BO_ 437 FR_CMR_03_50ms: 32 FR_CMR
 SG_ ID_CIPV : 192|7@1+ (1,0) [0|127] "" Dummy
 SG_ Relative_Velocity : 200|12@1+ (0.05,-100) [-100|104.75] "m/s" Dummy
 SG_ Longitudinal_Distance : 212|12@1+ (0.05,0) [0|204.75] "m" Dummy

BO_ 442 BLINDSPOTS_REAR_CORNERS: 24 XXX
 SG_ CHECKSUM : 0|16@1+ (1,0) [0|65535] "" XXX
 SG_ COUNTER : 16|8@1+ (1,0) [0|255] "" XXX
 SG_ LEFT_BLOCKED : 24|1@0+ (1,0) [0|1] "" XXX
 SG_ LEFT_MB : 30|1@0+ (1,0) [0|3] "" XXX
 SG_ MORE_LEFT_PROB : 32|1@1+ (1,0) [0|3] "" XXX
 SG_ FL_INDICATOR : 46|6@0+ (1,0) [0|1] "" XXX
 SG_ FR_INDICATOR : 54|6@0+ (1,0) [0|63] "" XXX
 SG_ RIGHT_BLOCKED : 64|1@0+ (1,0) [0|1] "" XXX
 SG_ COLLISION_AVOIDANCE_ACTIVE : 68|1@0+ (1,0) [0|1] "" XXX
 SG_ NEW_SIGNAL_2 : 96|1@0+ (1,0) [0|1] "" XXX
 SG_ FL_INDICATOR_ALT : 138|1@0+ (1,0) [0|1] "" XXX
 SG_ FR_INDICATOR_ALT : 141|1@0+ (1,0) [0|1] "" XXX

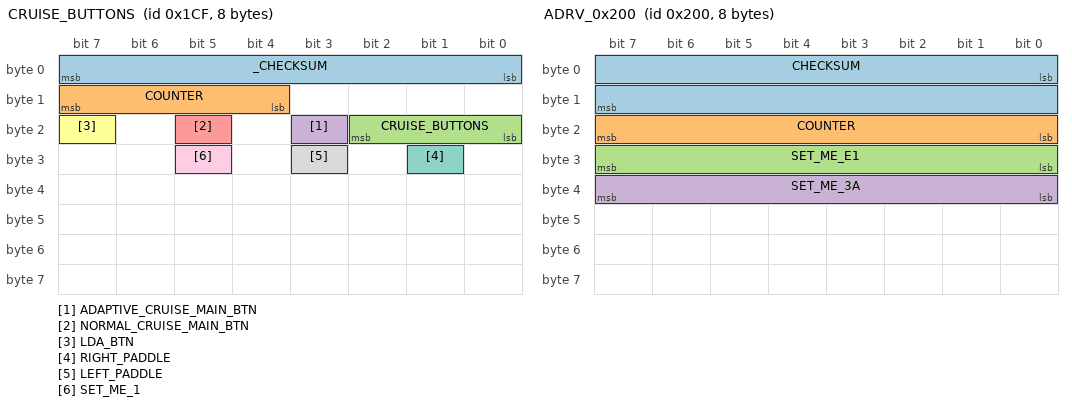
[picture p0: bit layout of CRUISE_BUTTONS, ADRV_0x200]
BO_ 463 CRUISE_BUTTONS: 8 XXX
 SG_ _CHECKSUM : 0|8@1+ (1,0) [0|65535] "" XXX
 SG_ COUNTER : 12|4@1+ (1,0) [0|255] "" XXX
 SG_ CRUISE_BUTTONS : 16|3@1+ (1,0) [0|3] "" XXX
 SG_ ADAPTIVE_CRUISE_MAIN_BTN : 19|1@1+ (1,0) [0|1] "" XXX
 SG_ NORMAL_CRUISE_MAIN_BTN : 21|1@1+ (1,0) [0|1] "" XXX
 SG_ LDA_BTN : 23|1@1+ (1,0) [0|1] "" XXX
 SG_ RIGHT_PADDLE : 25|1@1+ (1,0) [0|1] "" XXX
 SG_ LEFT_PADDLE : 27|1@1+ (1,0) [0|1] "" XXX
 SG_ SET_ME_1 : 29|1@1+ (1,0) [0|1] "" XXX

BO_ 474 ADRV_0x1da: 32 ADRV
 SG_ CHECKSUM : 0|16@1+ (1,0) [0|65535] "" XXX
 SG_ COUNTER : 16|8@1+ (1,0) [0|255] "" XXX
 SG_ SET_ME_22 : 31|8@0+ (1,0) [0|255] "" XXX
 SG_ SET_ME_41 : 47|8@0+ (1,0) [0|255] "" XXX

BO_ 480 LFAHDA_CLUSTER: 16 ADRV
 SG_ CHECKSUM : 0|16@1+ (1,0) [0|65535] "" XXX
 SG_ COUNTER : 16|8@1+ (1,0) [0|255] "" XXX
 SG_ NEW_SIGNAL_4 : 24|1@0+ (1,0) [0|1] "" XXX
 SG_ NEW_SIGNAL_5 : 25|1@0+ (1,0) [0|1] "" XXX
 SG_ NEW_SIGNAL_2 : 30|1@0+ (1,0) [0|1] "" XXX
 SG_ HDA_ICON : 31|1@1+ (1,0) [0|1] "" XXX
 SG_ NEW_SIGNAL_1 : 32|3@1+ (1,0) [0|7] "" XXX
 SG_ LFA_ICON : 47|2@1+ (1,0) [0|3] "" XXX
 SG_ NEW_SIGNAL_3 : 49|1@0+ (1,0) [0|1] "" XXX

BO_ 485 BLINDSPOTS_FRONT_CORNER_1: 16 XXX
 SG_ CHECKSUM : 0|16@1+ (1,0) [0|65535] "" XXX
 SG_ COUNTER : 16|8@1+ (1,0) [0|255] "" XXX
 SG_ REVERSING : 24|1@0+ (1,0) [0|1] "" XXX
 SG_ NEW_SIGNAL_5 : 31|2@0+ (1,0) [0|3] "" XXX
 SG_ NEW_SIGNAL_7 : 32|2@1+ (1,0) [0|3] "" XXX
 SG_ NEW_SIGNAL_8 : 47|8@0+ (1,0) [0|255] "" XXX
 SG_ NEW_SIGNAL_9 : 55|8@0+ (1,0) [0|255] "" XXX
 SG_ NEW_SIGNAL_4 : 80|1@0+ (1,0) [0|1] "" XXX
 SG_ NEW_SIGNAL_3 : 88|1@0+ (1,0) [0|1] "" XXX
 SG_ NEW_SIGNAL_2 : 96|1@0+ (1,0) [0|1] "" XXX
 SG_ NEW_SIGNAL_1 : 108|2@0+ (1,0) [0|3] "" XXX

BO_ 490 ADRV_0x1ea: 32 ADRV
 SG_ CHECKSUM : 0|16@1+ (1,0) [0|65535] "" XXX
 SG_ COUNTER : 16|8@1+ (1,0) [0|255] "" XXX
 SG_ SET_ME_1C : 31|8@0+ (1,0) [0|255] "" XXX
 SG_ NEW_SIGNAL_1 : 32|2@1+ (1,0) [0|3] "" XXX
 SG_ NEW_SIGNAL_2 : 47|2@0+ (1,0) [0|3] "" XXX
 SG_ NEW_SIGNAL_3 : 55|8@0+ (1,0) [0|255] "" XXX
 SG_ NEW_SIGNAL_4 : 64|6@1+ (1,0) [0|31] "" XXX
 SG_ NEW_SIGNAL_5 : 72|2@1+ (1,0) [0|3] "" XXX
 SG_ NEW_SIGNAL_6 : 75|5@1+ (1,0) [0|31] "" XXX
 SG_ NEW_SIGNAL_7 : 80|5@1+ (1,0) [0|31] "" XXX
 SG_ NEW_SIGNAL_8 : 88|7@1+ (1,0) [0|127] "" XXX
 SG_ NEW_SIGNAL_9 : 96|1@0+ (1,0) [0|1] "" XXX
 SG_ SET_ME_FF : 120|8@1+ (1,0) [0|255] "" XXX
 SG_ NEW_SIGNAL_10 : 143|5@0+ (1,0) [0|31] "" XXX
 SG_ NEW_SIGNAL_11 : 144|3@1+ (1,0) [0|7] "" XXX
 SG_ NEW_SIGNAL_12 : 152|6@1+ (1,0) [0|63] "" XXX
 SG_ NEW_SIGNAL_13 : 160|1@0+ (1,0) [0|1] "" XXX
 SG_ NEW_SIGNAL_14 : 163|5@1+ (1,0) [0|31] "" XXX
 SG_ NEW_SIGNAL_16 : 168|3@1+ (1,0) [0|7] "" XXX
 SG_ NEW_SIGNAL_15 : 175|4@0+ (1,0) [0|63] "" XXX
 SG_ NEW_SIGNAL_17 : 176|2@1+ (1,0) [0|3] "" XXX
 SG_ NEW_SIGNAL_18 : 184|1@0+ (1,0) [0|1] "" XXX
 SG_ NEW_SIGNAL_19 : 208|3@1+ (1,0) [0|7] "" XXX
 SG_ NEW_SIGNAL_20 : 212|1@0+ (1,0) [0|1] "" XXX
 SG_ SET_ME_TMP_F : 232|5@1+ (1,0) [0|31] "" XXX
 SG_ SET_ME_TMP_F_2 : 240|5@1+ (1,0) [0|31] "" XXX

BO_ 506 FR_CMR_02_100ms: 32 FR_CMR
 SG_ FR_CMR_Crc2Val : 0|16@1+ (1,0) [0|65535] "" CGW
 SG_ FR_CMR_AlvCnt2Val : 16|8@1+ (1,0) [0|255] "" CGW
 SG_ ISLW_OptUsmSta : 24|2@1+ (1,0) [0|3] "" CLU,CGW
 SG_ ISLW_SysSta : 26|2@1+ (1,0) [0|3] "" CLU,CGW
 SG_ ISLW_NoPassingInfoDis : 28|3@1+ (1,0) [0|7] "" CLU,CGW
 SG_ ISLW_OvrlpSignDis : 31|2@1+ (1,0) [0|3] "" CLU,CGW
 SG_ ISLW_SpdCluMainDis : 33|8@1+ (1,0) [0|255] "" CLU,CGW
 SG_ ISLW_SpdNaviMainDis : 41|8@1+ (1,0) [0|255] "" CGW
 SG_ ISLW_SubCondinfoSta1 : 49|4@1+ (1,0) [0|15] "" CLU,CGW
 SG_ ISLW_SubCondinfoSta2 : 53|4@1+ (1,0) [0|15] "" CLU,CGW
 SG_ ISLW_SpdCluSubMainDis : 64|8@1+ (1,0) [0|255] "" CLU
 SG_ ISLW_SpdCluDisSubCond1 : 72|8@1+ (1,0) [0|255] "" CLU,CGW
 SG_ ISLW_SpdCluDisSubCond2 : 80|8@1+ (1,0) [0|255] "" CLU,CGW
 SG_ ISLW_SpdNaviSubMainDis : 88|8@1+ (1,0) [0|255] "" CLU
 SG_ ISLW_SpdNaviDisSubCond1 : 96|8@1+ (1,0) [0|255] "" CLU,CGW
 SG_ ISLW_SpdNaviDisSubCond2 : 104|8@1+ (1,0) [0|255] "" CLU,CGW
 SG_ ISLA_SpdwOffst : 112|8@1+ (1,0) [0|255] "" CLU,CGW
 SG_ ISLA_SwIgnoreReq : 120|2@1+ (1,0) [0|3] "" CGW
 SG_ ISLA_SpdChgReq : 122|2@1+ (1,0) [0|3] "" CGW
 SG_ ISLA_SpdWrn : 124|2@1+ (1,0) [0|3] "" CLU,CGW
 SG_ ISLA_IcyWrn : 126|2@1+ (1,0) [0|3] "" CLU,CGW
 SG_ ISLA_SymFlashMod : 128|3@1+ (1,0) [0|7] "" CLU,CGW
 SG_ ISLA_Popup : 131|3@1+ (1,0) [0|7] "" CLU
 SG_ ISLA_OptUsmSta : 136|3@1+ (1,0) [0|7] "" CLU,CGW
 SG_ ISLA_OffstUsmSta : 139|3@1+ (1,0) [0|7] "" CLU,CGW
 SG_ ISLA_AutoUsmSta : 142|2@1+ (1,0) [0|3] "" CLU,CGW
 SG_ ISLA_Cntry : 144|4@1+ (1,0) [0|15] "" CLU,CGW
 SG_ ISLA_AddtnlSign : 149|5@1+ (1,0) [0|31] "" CLU,CGW
 SG_ ISLA_SchoolZone : 154|2@1+ (1,0) [0|3] "" CLU,CGW

BO_ 507 CAM_0x1fb: 32 CAMERA
 SG_ CHECKSUM : 0|16@1+ (1,0) [0|65535] "" XXX
 SG_ COUNTER : 16|8@1+ (1,0) [0|255] "" XXX

BO_ 512 ADRV_0x200: 8 ADRV
 SG_ CHECKSUM : 0|16@1+ (1,0) [0|65535] "" XXX
 SG_ COUNTER : 16|8@1+ (1,0) [0|255] "" XXX
 SG_ SET_ME_E1 : 24|8@1+ (1,0) [0|255] "" XXX
 SG_ SET_ME_3A : 32|8@1+ (1,0) [0|255] "" XXX

BO_ 593 RADAR_0x251: 16 FRONT_RADAR
 SG_ CHECKSUM : 0|16@1+ (1,0) [0|65535] "" XXX
 SG_ COUNTER : 16|8@1+ (1,0) [0|255] "" XXX

CM_ SG_ 480 NEW_SIGNAL_5 "todo: figure out why always set to 1";
VAL_ 463 CRUISE_BUTTONS 0 "none" 1 "res_accel" 2 "set_decel" 3 "gap_distance" 4 "pause_resume";
VAL_ 463 RIGHT_PADDLE 0 "Not Pulled" 1 "Pulled";
VAL_ 463 LEFT_PADDLE 0 "Not Pulled" 1 "Pulled";
VAL_ 506 ISLW_OptUsmSta 0 "None ISLW Option (Default)" 1 "System Disabled by USM" 2 "System Enable by USM" 3 "Invalid";
VAL_ 506 ISLW_SysSta 0 "Normal (Default)" 1 "System Fail" 2 "ISLW Temporary Unavailable" 3 "Reserved";
VAL_ 506 ISLW_NoPassingInfoDis 0 "None Display (Default)" 1 "LHD No Passing Zone Display" 2 "RHD No Passing Zone Display" 3 "Reserved" 4 "Reserved" 5 "Reserved" 6 "Reserved" 7 "Invalid";
VAL_ 506 ISLW_OvrlpSignDis 0 "None (Default)" 1 "Overlap Sign" 2 "Reserved" 3 "Error indicator";
VAL_ 506 ISLW_SpdCluMainDis 0 "No Recognition (Default)" 1 "1~252" 2 "1~252" 3 "1~252" 4 "1~252" 5 "1~252" 6 "1~252" 7 "1~252" 8 "1~252" 9 "1~252" 10 "1~252" 11 "1~252" 12 "1~252" 13 "1~252" 14 "1~252" 15 "1~252" 16 "1~252" 17 "1~252" 18 "1~252" 19 "1~252" 20 "1~252" 21 "1~252" 22 "1~252" 23 "1~252" 24 "1~252" 25 "1~252" 26 "1~252" 27 "1~252" 28 "1~252" 29 "1~252" 30 "1~252" 31 "1~252" 32 "1~252" 33 "1~252" 34 "1~252" 35 "1~252" 36 "1~252" 37 "1~252" 38 "1~252" 39 "1~252" 40 "1~252" 41 "1~252" 42 "1~252" 43 "1~252" 44 "1~252" 45 "1~252" 46 "1~252" 47 "1~252" 48 "1~252" 49 "1~252" 50 "1~252" 51 "1~252" 52 "1~252" 53 "1~252" 54 "1~252" 55 "1~252" 56 "1~252" 57 "1~252" 58 "1~252" 59 "1~252" 60 "1~252" 61 "1~252" 62 "1~252" 63 "1~252" 64 "1~252" 65 "1~252" 66 "1~252" 67 "1~252" 68 "1~252" 69 "1~252" 70 "1~252" 71 "1~252" 72 "1~252" 73 "1~252" 74 "1~252" 75 "1~252" 76 "1~252" 77 "1~252" 78 "1~252" 79 "1~252" 80 "1~252" 81 "1~252" 82 "1~252" 83 "1~252" 84 "1~252" 85 "1~252" 86 "1~252" 87 "1~252" 88 "1~252" 89 "1~252" 90 "1~252" 91 "1~252" 92 "1~252" 93 "1~252" 94 "1~252" 95 "1~252" 96 "1~252" 97 "1~252" 98 "1~252" 99 "1~252" 100 "1~252" 101 "1~252" 102 "1~252" 103 "1~252" 104 "1~252" 105 "1~252" 106 "1~252" 107 "1~252" 108 "1~252" 109 "1~252" 110 "1~252" 111 "1~252" 112 "1~252" 113 "1~252" 114 "1~252" 115 "1~252" 116 "1~252" 117 "1~252" 118 "1~252" 119 "1~252" 120 "1~252" 121 "1~252" 122 "1~252" 123 "1~252" 124 "1~252" 125 "1~252" 126 "1~252" 127 "1~252" 128 "1~252" 129 "1~252" 130 "1~252" 131 "1~252" 132 "1~252" 133 "1~252" 134 "1~252" 135 "1~252" 136 "1~252" 137 "1~252" 138 "1~252" 139 "1~252" 140 "1~252" 141 "1~252" 142 "1~252" 143 "1~252" 144 "1~252" 145 "1~252" 146 "1~252" 147 "1~252" 148 "1~252" 149 "1~252" 150 "1~252" 151 "1~252" 152 "1~252" 153 "1~252" 154 "1~252" 155 "1~252" 156 "1~252" 157 "1~252" 158 "1~252" 159 "1~252" 160 "1~252" 161 "1~252" 162 "1~252" 163 "1~252" 164 "1~252" 165 "1~252" 166 "1~252" 167 "1~252" 168 "1~252" 169 "1~252" 170 "1~252" 171 "1~252" 172 "1~252" 173 "1~252" 174 "1~252" 175 "1~252" 176 "1~252" 177 "1~252" 178 "1~252" 179 "1~252" 180 "1~252" 181 "1~252" 182 "1~252" 183 "1~252" 184 "1~252" 185 "1~252" 186 "1~252" 187 "1~252" 188 "1~252" 189 "1~252" 190 "1~252" 191 "1~252" 192 "1~252" 193 "1~252" 194 "1~252" 195 "1~252" 196 "1~252" 197 "1~252" 198 "1~252" 199 "1~252" 200 "1~252" 201 "1~252" 202 "1~252" 203 "1~252" 204 "1~252" 205 "1~252" 206 "1~252" 207 "1~252" 208 "1~252" 209 "1~252" 210 "1~252" 211 "1~252" 212 "1~252" 213 "1~252" 214 "1~252" 215 "1~252" 216 "1~252" 217 "1~252" 218 "1~252" 219 "1~252" 220 "1~252" 221 "1~252" 222 "1~252" 223 "1~252" 224 "1~252" 225 "1~252" 226 "1~252" 227 "1~252" 228 "1~252" 229 "1~252" 230 "1~252" 231 "1~252" 232 "1~252" 233 "1~252" 234 "1~252" 235 "1~252" 236 "1~252" 237 "1~252" 238 "1~252" 239 "1~252" 240 "1~252" 241 "1~252" 242 "1~252" 243 "1~252" 244 "1~252" 245 "1~252" 246 "1~252" 247 "1~252" 248 "1~252" 249 "1~252" 250 "1~252" 251 "1~252" 252 "1~252" 253 "Unlimited Speed" 254 "Reserved" 255 "Invalid";
VAL_ 506 ISLW_SpdNaviMainDis 0 "No Recognition (Default)" 1 "1~252" 2 "1~252" 3 "1~252" 4 "1~252" 5 "1~252" 6 "1~252" 7 "1~252" 8 "1~252" 9 "1~252" 10 "1~252" 11 "1~252" 12 "1~252" 13 "1~252" 14 "1~252" 15 "1~252" 16 "1~252" 17 "1~252" 18 "1~252" 19 "1~252" 20 "1~252" 21 "1~252" 22 "1~252" 23 "1~252" 24 "1~252" 25 "1~252" 26 "1~252" 27 "1~252" 28 "1~252" 29 "1~252" 30 "1~252" 31 "1~252" 32 "1~252" 33 "1~252" 34 "1~252" 35 "1~252" 36 "1~252" 37 "1~252" 38 "1~252" 39 "1~252" 40 "1~252" 41 "1~252" 42 "1~252" 43 "1~252" 44 "1~252" 45 "1~252" 46 "1~252" 47 "1~252" 48 "1~252" 49 "1~252" 50 "1~252" 51 "1~252" 52 "1~252" 53 "1~252" 54 "1~252" 55 "1~252" 56 "1~252" 57 "1~252" 58 "1~252" 59 "1~252" 60 "1~252" 61 "1~252" 62 "1~252" 63 "1~252" 64 "1~252" 65 "1~252" 66 "1~252" 67 "1~252" 68 "1~252" 69 "1~252" 70 "1~252" 71 "1~252" 72 "1~252" 73 "1~252" 74 "1~252" 75 "1~252" 76 "1~252" 77 "1~252" 78 "1~252" 79 "1~252" 80 "1~252" 81 "1~252" 82 "1~252" 83 "1~252" 84 "1~252" 85 "1~252" 86 "1~252" 87 "1~252" 88 "1~252" 89 "1~252" 90 "1~252" 91 "1~252" 92 "1~252" 93 "1~252" 94 "1~252" 95 "1~252" 96 "1~252" 97 "1~252" 98 "1~252" 99 "1~252" 100 "1~252" 101 "1~252" 102 "1~252" 103 "1~252" 104 "1~252" 105 "1~252" 106 "1~252" 107 "1~252" 108 "1~252" 109 "1~252" 110 "1~252" 111 "1~252" 112 "1~252" 113 "1~252" 114 "1~252" 115 "1~252" 116 "1~252" 117 "1~252" 118 "1~252" 119 "1~252" 120 "1~252" 121 "1~252" 122 "1~252" 123 "1~252" 124 "1~252" 125 "1~252" 126 "1~252" 127 "1~252" 128 "1~252" 129 "1~252" 130 "1~252" 131 "1~252" 132 "1~252" 133 "1~252" 134 "1~252" 135 "1~252" 136 "1~252" 137 "1~252" 138 "1~252" 139 "1~252" 140 "1~252" 141 "1~252" 142 "1~252" 143 "1~252" 144 "1~252" 145 "1~252" 146 "1~252" 147 "1~252" 148 "1~252" 149 "1~252" 150 "1~252" 151 "1~252" 152 "1~252" 153 "1~252" 154 "1~252" 155 "1~252" 156 "1~252" 157 "1~252" 158 "1~252" 159 "1~252" 160 "1~252" 161 "1~252" 162 "1~252" 163 "1~252" 164 "1~252" 165 "1~252" 166 "1~252" 167 "1~252" 168 "1~252" 169 "1~252" 170 "1~252" 171 "1~252" 172 "1~252" 173 "1~252" 174 "1~252" 175 "1~252" 176 "1~252" 177 "1~252" 178 "1~252" 179 "1~252" 180 "1~252" 181 "1~252" 182 "1~252" 183 "1~252" 184 "1~252" 185 "1~252" 186 "1~252" 187 "1~252" 188 "1~252" 189 "1~252" 190 "1~252" 191 "1~252" 192 "1~252" 193 "1~252" 194 "1~252" 195 "1~252" 196 "1~252" 197 "1~252" 198 "1~252" 199 "1~252" 200 "1~252" 201 "1~252" 202 "1~252" 203 "1~252" 204 "1~252" 205 "1~252" 206 "1~252" 207 "1~252" 208 "1~252" 209 "1~252" 210 "1~252" 211 "1~252" 212 "1~252" 213 "1~252" 214 "1~252" 215 "1~252" 216 "1~252" 217 "1~252" 218 "1~252" 219 "1~252" 220 "1~252" 221 "1~252" 222 "1~252" 223 "1~252" 224 "1~252" 225 "1~252" 226 "1~252" 227 "1~252" 228 "1~252" 229 "1~252" 230 "1~252" 231 "1~252" 232 "1~252" 233 "1~252" 234 "1~252" 235 "1~252" 236 "1~252" 237 "1~252" 238 "1~252" 239 "1~252" 240 "1~252" 241 "1~252" 242 "1~252" 243 "1~252" 244 "1~252" 245 "1~252" 246 "1~252" 247 "1~252" 248 "1~252" 249 "1~252" 250 "1~252" 251 "1~252" 252 "1~252" 253 "Unlimited Speed" 254 "Reserved" 255 "Invalid";
VAL_ 506 ISLW_SubCondinfoSta1 0 "None (Default)" 1 "Rain" 2 "Snow" 3 "Snow&Rain" 4 "Trailer" 5 "Reserved" 6 "Reserved" 7 "Reserved" 8 "Reserved" 9 "Reserved" 10 "Reserved" 11 "Reserved" 12 "Reserved" 13 "Reserved" 14 "Generic" 15 "Invalid";
VAL_ 506 ISLW_SubCondinfoSta2 0 "None (Default)" 1 "Rain" 2 "Snow" 3 "Snow&Rain" 4 "Trailer" 5 "Reserved" 6 "Reserved" 7 "Reserved" 8 "Reserved" 9 "Reserved" 10 "Reserved" 11 "Reserved" 12 "Reserved" 13 "Reserved" 14 "Generic" 15 "Invalid";
VAL_ 506 ISLW_SpdCluSubMainDis 0 "No Recognition (Default)" 1 "1~252" 2 "1~252" 3 "1~252" 4 "1~252" 5 "1~252" 6 "1~252" 7 "1~252" 8 "1~252" 9 "1~252" 10 "1~252" 11 "1~252" 12 "1~252" 13 "1~252" 14 "1~252" 15 "1~252" 16 "1~252" 17 "1~252" 18 "1~252" 19 "1~252" 20 "1~252" 21 "1~252" 22 "1~252" 23 "1~252" 24 "1~252" 25 "1~252" 26 "1~252" 27 "1~252" 28 "1~252" 29 "1~252" 30 "1~252" 31 "1~252" 32 "1~252" 33 "1~252" 34 "1~252" 35 "1~252" 36 "1~252" 37 "1~252" 38 "1~252" 39 "1~252" 40 "1~252" 41 "1~252" 42 "1~252" 43 "1~252" 44 "1~252" 45 "1~252" 46 "1~252" 47 "1~252" 48 "1~252" 49 "1~252" 50 "1~252" 51 "1~252" 52 "1~252" 53 "1~252" 54 "1~252" 55 "1~252" 56 "1~252" 57 "1~252" 58 "1~252" 59 "1~252" 60 "1~252" 61 "1~252" 62 "1~252" 63 "1~252" 64 "1~252" 65 "1~252" 66 "1~252" 67 "1~252" 68 "1~252" 69 "1~252" 70 "1~252" 71 "1~252" 72 "1~252" 73 "1~252" 74 "1~252" 75 "1~252" 76 "1~252" 77 "1~252" 78 "1~252" 79 "1~252" 80 "1~252" 81 "1~252" 82 "1~252" 83 "1~252" 84 "1~252" 85 "1~252" 86 "1~252" 87 "1~252" 88 "1~252" 89 "1~252" 90 "1~252" 91 "1~252" 92 "1~252" 93 "1~252" 94 "1~252" 95 "1~252" 96 "1~252" 97 "1~252" 98 "1~252" 99 "1~252" 100 "1~252" 101 "1~252" 102 "1~252" 103 "1~252" 104 "1~252" 105 "1~252" 106 "1~252" 107 "1~252" 108 "1~252" 109 "1~252" 110 "1~252" 111 "1~252" 112 "1~252" 113 "1~252" 114 "1~252" 115 "1~252" 116 "1~252" 117 "1~252" 118 "1~252" 119 "1~252" 120 "1~252" 121 "1~252" 122 "1~252" 123 "1~252" 124 "1~252" 125 "1~252" 126 "1~252" 127 "1~252" 128 "1~252" 129 "1~252" 130 "1~252" 131 "1~252" 132 "1~252" 133 "1~252" 134 "1~252" 135 "1~252" 136 "1~252" 137 "1~252" 138 "1~252" 139 "1~252" 140 "1~252" 141 "1~252" 142 "1~252" 143 "1~252" 144 "1~252" 145 "1~252" 146 "1~252" 147 "1~252" 148 "1~252" 149 "1~252" 150 "1~252" 151 "1~252" 152 "1~252" 153 "1~252" 154 "1~252" 155 "1~252" 156 "1~252" 157 "1~252" 158 "1~252" 159 "1~252" 160 "1~252" 161 "1~252" 162 "1~252" 163 "1~252" 164 "1~252" 165 "1~252" 166 "1~252" 167 "1~252" 168 "1~252" 169 "1~252" 170 "1~252" 171 "1~252" 172 "1~252" 173 "1~252" 174 "1~252" 175 "1~252" 176 "1~252" 177 "1~252" 178 "1~252" 179 "1~252" 180 "1~252" 181 "1~252" 182 "1~252" 183 "1~252" 184 "1~252" 185 "1~252" 186 "1~252" 187 "1~252" 188 "1~252" 189 "1~252" 190 "1~252" 191 "1~252" 192 "1~252" 193 "1~252" 194 "1~252" 195 "1~252" 196 "1~252" 197 "1~252" 198 "1~252" 199 "1~252" 200 "1~252" 201 "1~252" 202 "1~252" 203 "1~252" 204 "1~252" 205 "1~252" 206 "1~252" 207 "1~252" 208 "1~252" 209 "1~252" 210 "1~252" 211 "1~252" 212 "1~252" 213 "1~252" 214 "1~252" 215 "1~252" 216 "1~252" 217 "1~252" 218 "1~252" 219 "1~252" 220 "1~252" 221 "1~252" 222 "1~252" 223 "1~252" 224 "1~252" 225 "1~252" 226 "1~252" 227 "1~252" 228 "1~252" 229 "1~252" 230 "1~252" 231 "1~252" 232 "1~252" 233 "1~252" 234 "1~252" 235 "1~252" 236 "1~252" 237 "1~252" 238 "1~252" 239 "1~252" 240 "1~252" 241 "1~252" 242 "1~252" 243 "1~252" 244 "1~252" 245 "1~252" 246 "1~252" 247 "1~252" 248 "1~252" 249 "1~252" 250 "1~252" 251 "1~252" 252 "1~252" 253 "Unlimited Speed" 254 "Reserved" 255 "Invalid";
VAL_ 506 ISLW_SpdCluDisSubCond1 0 "No Recognition (Default)" 1 "1~252" 2 "1~252" 3 "1~252" 4 "1~252" 5 "1~252" 6 "1~252" 7 "1~252" 8 "1~252" 9 "1~252" 10 "1~252" 11 "1~252" 12 "1~252" 13 "1~252" 14 "1~252" 15 "1~252" 16 "1~252" 17 "1~252" 18 "1~252" 19 "1~252" 20 "1~252" 21 "1~252" 22 "1~252" 23 "1~252" 24 "1~252" 25 "1~252" 26 "1~252" 27 "1~252" 28 "1~252" 29 "1~252" 30 "1~252" 31 "1~252" 32 "1~252" 33 "1~252" 34 "1~252" 35 "1~252" 36 "1~252" 37 "1~252" 38 "1~252" 39 "1~252" 40 "1~252" 41 "1~252" 42 "1~252" 43 "1~252" 44 "1~252" 45 "1~252" 46 "1~252" 47 "1~252" 48 "1~252" 49 "1~252" 50 "1~252" 51 "1~252" 52 "1~252" 53 "1~252" 54 "1~252" 55 "1~252" 56 "1~252" 57 "1~252" 58 "1~252" 59 "1~252" 60 "1~252" 61 "1~252" 62 "1~252" 63 "1~252" 64 "1~252" 65 "1~252" 66 "1~252" 67 "1~252" 68 "1~252" 69 "1~252" 70 "1~252" 71 "1~252" 72 "1~252" 73 "1~252" 74 "1~252" 75 "1~252" 76 "1~252" 77 "1~252" 78 "1~252" 79 "1~252" 80 "1~252" 81 "1~252" 82 "1~252" 83 "1~252" 84 "1~252" 85 "1~252" 86 "1~252" 87 "1~252" 88 "1~252" 89 "1~252" 90 "1~252" 91 "1~252" 92 "1~252" 93 "1~252" 94 "1~252" 95 "1~252" 96 "1~252" 97 "1~252" 98 "1~252" 99 "1~252" 100 "1~252" 101 "1~252" 102 "1~252" 103 "1~252" 104 "1~252" 105 "1~252" 106 "1~252" 107 "1~252" 108 "1~252" 109 "1~252" 110 "1~252" 111 "1~252" 112 "1~252" 113 "1~252" 114 "1~252" 115 "1~252" 116 "1~252" 117 "1~252" 118 "1~252" 119 "1~252" 120 "1~252" 121 "1~252" 122 "1~252" 123 "1~252" 124 "1~252" 125 "1~252" 126 "1~252" 127 "1~252" 128 "1~252" 129 "1~252" 130 "1~252" 131 "1~252" 132 "1~252" 133 "1~252" 134 "1~252" 135 "1~252" 136 "1~252" 137 "1~252" 138 "1~252" 139 "1~252" 140 "1~252" 141 "1~252" 142 "1~252" 143 "1~252" 144 "1~252" 145 "1~252" 146 "1~252" 147 "1~252" 148 "1~252" 149 "1~252" 150 "1~252" 151 "1~252" 152 "1~252" 153 "1~252" 154 "1~252" 155 "1~252" 156 "1~252" 157 "1~252" 158 "1~252" 159 "1~252" 160 "1~252" 161 "1~252" 162 "1~252" 163 "1~252" 164 "1~252" 165 "1~252" 166 "1~252" 167 "1~252" 168 "1~252" 169 "1~252" 170 "1~252" 171 "1~252" 172 "1~252" 173 "1~252" 174 "1~252" 175 "1~252" 176 "1~252" 177 "1~252" 178 "1~252" 179 "1~252" 180 "1~252" 181 "1~252" 182 "1~252" 183 "1~252" 184 "1~252" 185 "1~252" 186 "1~252" 187 "1~252" 188 "1~252" 189 "1~252" 190 "1~252" 191 "1~252" 192 "1~252" 193 "1~252" 194 "1~252" 195 "1~252" 196 "1~252" 197 "1~252" 198 "1~252" 199 "1~252" 200 "1~252" 201 "1~252" 202 "1~252" 203 "1~252" 204 "1~252" 205 "1~252" 206 "1~252" 207 "1~252" 208 "1~252" 209 "1~252" 210 "1~252" 211 "1~252" 212 "1~252" 213 "1~252" 214 "1~252" 215 "1~252" 216 "1~252" 217 "1~252" 218 "1~252" 219 "1~252" 220 "1~252" 221 "1~252" 222 "1~252" 223 "1~252" 224 "1~252" 225 "1~252" 226 "1~252" 227 "1~252" 228 "1~252" 229 "1~252" 230 "1~252" 231 "1~252" 232 "1~252" 233 "1~252" 234 "1~252" 235 "1~252" 236 "1~252" 237 "1~252" 238 "1~252" 239 "1~252" 240 "1~252" 241 "1~252" 242 "1~252" 243 "1~252" 244 "1~252" 245 "1~252" 246 "1~252" 247 "1~252" 248 "1~252" 249 "1~252" 250 "1~252" 251 "1~252" 252 "1~252" 253 "LHD Conditional No Passing ZONE" 254 "RHD Conditional No Passing ZONE" 255 "Invalid";
VAL_ 506 ISLW_SpdCluDisSubCond2 0 "No Recognition (Default)" 1 "1~252" 2 "1~252" 3 "1~252" 4 "1~252" 5 "1~252" 6 "1~252" 7 "1~252" 8 "1~252" 9 "1~252" 10 "1~252" 11 "1~252" 12 "1~252" 13 "1~252" 14 "1~252" 15 "1~252" 16 "1~252" 17 "1~252" 18 "1~252" 19 "1~252" 20 "1~252" 21 "1~252" 22 "1~252" 23 "1~252" 24 "1~252" 25 "1~252" 26 "1~252" 27 "1~252" 28 "1~252" 29 "1~252" 30 "1~252" 31 "1~252" 32 "1~252" 33 "1~252" 34 "1~252" 35 "1~252" 36 "1~252" 37 "1~252" 38 "1~252" 39 "1~252" 40 "1~252" 41 "1~252" 42 "1~252" 43 "1~252" 44 "1~252" 45 "1~252" 46 "1~252" 47 "1~252" 48 "1~252" 49 "1~252" 50 "1~252" 51 "1~252" 52 "1~252" 53 "1~252" 54 "1~252" 55 "1~252" 56 "1~252" 57 "1~252" 58 "1~252" 59 "1~252" 60 "1~252" 61 "1~252" 62 "1~252" 63 "1~252" 64 "1~252" 65 "1~252" 66 "1~252" 67 "1~252" 68 "1~252" 69 "1~252" 70 "1~252" 71 "1~252" 72 "1~252" 73 "1~252" 74 "1~252" 75 "1~252" 76 "1~252" 77 "1~252" 78 "1~252" 79 "1~252" 80 "1~252" 81 "1~252" 82 "1~252" 83 "1~252" 84 "1~252" 85 "1~252" 86 "1~252" 87 "1~252" 88 "1~252" 89 "1~252" 90 "1~252" 91 "1~252" 92 "1~252" 93 "1~252" 94 "1~252" 95 "1~252" 96 "1~252" 97 "1~252" 98 "1~252" 99 "1~252" 100 "1~252" 101 "1~252" 102 "1~252" 103 "1~252" 104 "1~252" 105 "1~252" 106 "1~252" 107 "1~252" 108 "1~252" 109 "1~252" 110 "1~252" 111 "1~252" 112 "1~252" 113 "1~252" 114 "1~252" 115 "1~252" 116 "1~252" 117 "1~252" 118 "1~252" 119 "1~252" 120 "1~252" 121 "1~252" 122 "1~252" 123 "1~252" 124 "1~252" 125 "1~252" 126 "1~252" 127 "1~252" 128 "1~252" 129 "1~252" 130 "1~252" 131 "1~252" 132 "1~252" 133 "1~252" 134 "1~252" 135 "1~252" 136 "1~252" 137 "1~252" 138 "1~252" 139 "1~252" 140 "1~252" 141 "1~252" 142 "1~252" 143 "1~252" 144 "1~252" 145 "1~252" 146 "1~252" 147 "1~252" 148 "1~252" 149 "1~252" 150 "1~252" 151 "1~252" 152 "1~252" 153 "1~252" 154 "1~252" 155 "1~252" 156 "1~252" 157 "1~252" 158 "1~252" 159 "1~252" 160 "1~252" 161 "1~252" 162 "1~252" 163 "1~252" 164 "1~252" 165 "1~252" 166 "1~252" 167 "1~252" 168 "1~252" 169 "1~252" 170 "1~252" 171 "1~252" 172 "1~252" 173 "1~252" 174 "1~252" 175 "1~252" 176 "1~252" 177 "1~252" 178 "1~252" 179 "1~252" 180 "1~252" 181 "1~252" 182 "1~252" 183 "1~252" 184 "1~252" 185 "1~252" 186 "1~252" 187 "1~252" 188 "1~252" 189 "1~252" 190 "1~252" 191 "1~252" 192 "1~252" 193 "1~252" 194 "1~252" 195 "1~252" 196 "1~252" 197 "1~252" 198 "1~252" 199 "1~252" 200 "1~252" 201 "1~252" 202 "1~252" 203 "1~252" 204 "1~252" 205 "1~252" 206 "1~252" 207 "1~252" 208 "1~252" 209 "1~252" 210 "1~252" 211 "1~252" 212 "1~252" 213 "1~252" 214 "1~252" 215 "1~252" 216 "1~252" 217 "1~252" 218 "1~252" 219 "1~252" 220 "1~252" 221 "1~252" 222 "1~252" 223 "1~252" 224 "1~252" 225 "1~252" 226 "1~252" 227 "1~252" 228 "1~252" 229 "1~252" 230 "1~252" 231 "1~252" 232 "1~252" 233 "1~252" 234 "1~252" 235 "1~252" 236 "1~252" 237 "1~252" 238 "1~252" 239 "1~252" 240 "1~252" 241 "1~252" 242 "1~252" 243 "1~252" 244 "1~252" 245 "1~252" 246 "1~252" 247 "1~252" 248 "1~252" 249 "1~252" 250 "1~252" 251 "1~252" 252 "1~252" 253 "LHD Conditional No Passing ZONE" 254 "RHD Conditional No Passing ZONE" 255 "Invalid";
VAL_ 506 ISLW_SpdNaviSubMainDis 0 "No Recognition (Default)" 1 "1~252" 2 "1~252" 3 "1~252" 4 "1~252" 5 "1~252" 6 "1~252" 7 "1~252" 8 "1~252" 9 "1~252" 10 "1~252" 11 "1~252" 12 "1~252" 13 "1~252" 14 "1~252" 15 "1~252" 16 "1~252" 17 "1~252" 18 "1~252" 19 "1~252" 20 "1~252" 21 "1~252" 22 "1~252" 23 "1~252" 24 "1~252" 25 "1~252" 26 "1~252" 27 "1~252" 28 "1~252" 29 "1~252" 30 "1~252" 31 "1~252" 32 "1~252" 33 "1~252" 34 "1~252" 35 "1~252" 36 "1~252" 37 "1~252" 38 "1~252" 39 "1~252" 40 "1~252" 41 "1~252" 42 "1~252" 43 "1~252" 44 "1~252" 45 "1~252" 46 "1~252" 47 "1~252" 48 "1~252" 49 "1~252" 50 "1~252" 51 "1~252" 52 "1~252" 53 "1~252" 54 "1~252" 55 "1~252" 56 "1~252" 57 "1~252" 58 "1~252" 59 "1~252" 60 "1~252" 61 "1~252" 62 "1~252" 63 "1~252" 64 "1~252" 65 "1~252" 66 "1~252" 67 "1~252" 68 "1~252" 69 "1~252" 70 "1~252" 71 "1~252" 72 "1~252" 73 "1~252" 74 "1~252" 75 "1~252" 76 "1~252" 77 "1~252" 78 "1~252" 79 "1~252" 80 "1~252" 81 "1~252" 82 "1~252" 83 "1~252" 84 "1~252" 85 "1~252" 86 "1~252" 87 "1~252" 88 "1~252" 89 "1~252" 90 "1~252" 91 "1~252" 92 "1~252" 93 "1~252" 94 "1~252" 95 "1~252" 96 "1~252" 97 "1~252" 98 "1~252" 99 "1~252" 100 "1~252" 101 "1~252" 102 "1~252" 103 "1~252" 104 "1~252" 105 "1~252" 106 "1~252" 107 "1~252" 108 "1~252" 109 "1~252" 110 "1~252" 111 "1~252" 112 "1~252" 113 "1~252" 114 "1~252" 115 "1~252" 116 "1~252" 117 "1~252" 118 "1~252" 119 "1~252" 120 "1~252" 121 "1~252" 122 "1~252" 123 "1~252" 124 "1~252" 125 "1~252" 126 "1~252" 127 "1~252" 128 "1~252" 129 "1~252" 130 "1~252" 131 "1~252" 132 "1~252" 133 "1~252" 134 "1~252" 135 "1~252" 136 "1~252" 137 "1~252" 138 "1~252" 139 "1~252" 140 "1~252" 141 "1~252" 142 "1~252" 143 "1~252" 144 "1~252" 145 "1~252" 146 "1~252" 147 "1~252" 148 "1~252" 149 "1~252" 150 "1~252" 151 "1~252" 152 "1~252" 153 "1~252" 154 "1~252" 155 "1~252" 156 "1~252" 157 "1~252" 158 "1~252" 159 "1~252" 160 "1~252" 161 "1~252" 162 "1~252" 163 "1~252" 164 "1~252" 165 "1~252" 166 "1~252" 167 "1~252" 168 "1~252" 169 "1~252" 170 "1~252" 171 "1~252" 172 "1~252" 173 "1~252" 174 "1~252" 175 "1~252" 176 "1~252" 177 "1~252" 178 "1~252" 179 "1~252" 180 "1~252" 181 "1~252" 182 "1~252" 183 "1~252" 184 "1~252" 185 "1~252" 186 "1~252" 187 "1~252" 188 "1~252" 189 "1~252" 190 "1~252" 191 "1~252" 192 "1~252" 193 "1~252" 194 "1~252" 195 "1~252" 196 "1~252" 197 "1~252" 198 "1~252" 199 "1~252" 200 "1~252" 201 "1~252" 202 "1~252" 203 "1~252" 204 "1~252" 205 "1~252" 206 "1~252" 207 "1~252" 208 "1~252" 209 "1~252" 210 "1~252" 211 "1~252" 212 "1~252" 213 "1~252" 214 "1~252" 215 "1~252" 216 "1~252" 217 "1~252" 218 "1~252" 219 "1~252" 220 "1~252" 221 "1~252" 222 "1~252" 223 "1~252" 224 "1~252" 225 "1~252" 226 "1~252" 227 "1~252" 228 "1~252" 229 "1~252" 230 "1~252" 231 "1~252" 232 "1~252" 233 "1~252" 234 "1~252" 235 "1~252" 236 "1~252" 237 "1~252" 238 "1~252" 239 "1~252" 240 "1~252" 241 "1~252" 242 "1~252" 243 "1~252" 244 "1~252" 245 "1~252" 246 "1~252" 247 "1~252" 248 "1~252" 249 "1~252" 250 "1~252" 251 "1~252" 252 "1~252" 253 "Unlimited Speed" 254 "Reserved" 255 "Invalid";
VAL_ 506 ISLW_SpdNaviDisSubCond1 0 "No Recognition (Default)" 1 "1~252" 2 "1~252" 3 "1~252" 4 "1~252" 5 "1~252" 6 "1~252" 7 "1~252" 8 "1~252" 9 "1~252" 10 "1~252" 11 "1~252" 12 "1~252" 13 "1~252" 14 "1~252" 15 "1~252" 16 "1~252" 17 "1~252" 18 "1~252" 19 "1~252" 20 "1~252" 21 "1~252" 22 "1~252" 23 "1~252" 24 "1~252" 25 "1~252" 26 "1~252" 27 "1~252" 28 "1~252" 29 "1~252" 30 "1~252" 31 "1~252" 32 "1~252" 33 "1~252" 34 "1~252" 35 "1~252" 36 "1~252" 37 "1~252" 38 "1~252" 39 "1~252" 40 "1~252" 41 "1~252" 42 "1~252" 43 "1~252" 44 "1~252" 45 "1~252" 46 "1~252" 47 "1~252" 48 "1~252" 49 "1~252" 50 "1~252" 51 "1~252" 52 "1~252" 53 "1~252" 54 "1~252" 55 "1~252" 56 "1~252" 57 "1~252" 58 "1~252" 59 "1~252" 60 "1~252" 61 "1~252" 62 "1~252" 63 "1~252" 64 "1~252" 65 "1~252" 66 "1~252" 67 "1~252" 68 "1~252" 69 "1~252" 70 "1~252" 71 "1~252" 72 "1~252" 73 "1~252" 74 "1~252" 75 "1~252" 76 "1~252" 77 "1~252" 78 "1~252" 79 "1~252" 80 "1~252" 81 "1~252" 82 "1~252" 83 "1~252" 84 "1~252" 85 "1~252" 86 "1~252" 87 "1~252" 88 "1~252" 89 "1~252" 90 "1~252" 91 "1~252" 92 "1~252" 93 "1~252" 94 "1~252" 95 "1~252" 96 "1~252" 97 "1~252" 98 "1~252" 99 "1~252" 100 "1~252" 101 "1~252" 102 "1~252" 103 "1~252" 104 "1~252" 105 "1~252" 106 "1~252" 107 "1~252" 108 "1~252" 109 "1~252" 110 "1~252" 111 "1~252" 112 "1~252" 113 "1~252" 114 "1~252" 115 "1~252" 116 "1~252" 117 "1~252" 118 "1~252" 119 "1~252" 120 "1~252" 121 "1~252" 122 "1~252" 123 "1~252" 124 "1~252" 125 "1~252" 126 "1~252" 127 "1~252" 128 "1~252" 129 "1~252" 130 "1~252" 131 "1~252" 132 "1~252" 133 "1~252" 134 "1~252" 135 "1~252" 136 "1~252" 137 "1~252" 138 "1~252" 139 "1~252" 140 "1~252" 141 "1~252" 142 "1~252" 143 "1~252" 144 "1~252" 145 "1~252" 146 "1~252" 147 "1~252" 148 "1~252" 149 "1~252" 150 "1~252" 151 "1~252" 152 "1~252" 153 "1~252" 154 "1~252" 155 "1~252" 156 "1~252" 157 "1~252" 158 "1~252" 159 "1~252" 160 "1~252" 161 "1~252" 162 "1~252" 163 "1~252" 164 "1~252" 165 "1~252" 166 "1~252" 167 "1~252" 168 "1~252" 169 "1~252" 170 "1~252" 171 "1~252" 172 "1~252" 173 "1~252" 174 "1~252" 175 "1~252" 176 "1~252" 177 "1~252" 178 "1~252" 179 "1~252" 180 "1~252" 181 "1~252" 182 "1~252" 183 "1~252" 184 "1~252" 185 "1~252" 186 "1~252" 187 "1~252" 188 "1~252" 189 "1~252" 190 "1~252" 191 "1~252" 192 "1~252" 193 "1~252" 194 "1~252" 195 "1~252" 196 "1~252" 197 "1~252" 198 "1~252" 199 "1~252" 200 "1~252" 201 "1~252" 202 "1~252" 203 "1~252" 204 "1~252" 205 "1~252" 206 "1~252" 207 "1~252" 208 "1~252" 209 "1~252" 210 "1~252" 211 "1~252" 212 "1~252" 213 "1~252" 214 "1~252" 215 "1~252" 216 "1~252" 217 "1~252" 218 "1~252" 219 "1~252" 220 "1~252" 221 "1~252" 222 "1~252" 223 "1~252" 224 "1~252" 225 "1~252" 226 "1~252" 227 "1~252" 228 "1~252" 229 "1~252" 230 "1~252" 231 "1~252" 232 "1~252" 233 "1~252" 234 "1~252" 235 "1~252" 236 "1~252" 237 "1~252" 238 "1~252" 239 "1~252" 240 "1~252" 241 "1~252" 242 "1~252" 243 "1~252" 244 "1~252" 245 "1~252" 246 "1~252" 247 "1~252" 248 "1~252" 249 "1~252" 250 "1~252" 251 "1~252" 252 "1~252" 253 "LHD Conditional No Passing ZONE" 254 "RHD Conditional No Passing ZONE" 255 "Invalid";
VAL_ 506 ISLW_SpdNaviDisSubCond2 0 "No Recognition (Default)" 1 "1~252" 2 "1~252" 3 "1~252" 4 "1~252" 5 "1~252" 6 "1~252" 7 "1~252" 8 "1~252" 9 "1~252" 10 "1~252" 11 "1~252" 12 "1~252" 13 "1~252" 14 "1~252" 15 "1~252" 16 "1~252" 17 "1~252" 18 "1~252" 19 "1~252" 20 "1~252" 21 "1~252" 22 "1~252" 23 "1~252" 24 "1~252" 25 "1~252" 26 "1~252" 27 "1~252" 28 "1~252" 29 "1~252" 30 "1~252" 31 "1~252" 32 "1~252" 33 "1~252" 34 "1~252" 35 "1~252" 36 "1~252" 37 "1~252" 38 "1~252" 39 "1~252" 40 "1~252" 41 "1~252" 42 "1~252" 43 "1~252" 44 "1~252" 45 "1~252" 46 "1~252" 47 "1~252" 48 "1~252" 49 "1~252" 50 "1~252" 51 "1~252" 52 "1~252" 53 "1~252" 54 "1~252" 55 "1~252" 56 "1~252" 57 "1~252" 58 "1~252" 59 "1~252" 60 "1~252" 61 "1~252" 62 "1~252" 63 "1~252" 64 "1~252" 65 "1~252" 66 "1~252" 67 "1~252" 68 "1~252" 69 "1~252" 70 "1~252" 71 "1~252" 72 "1~252" 73 "1~252" 74 "1~252" 75 "1~252" 76 "1~252" 77 "1~252" 78 "1~252" 79 "1~252" 80 "1~252" 81 "1~252" 82 "1~252" 83 "1~252" 84 "1~252" 85 "1~252" 86 "1~252" 87 "1~252" 88 "1~252" 89 "1~252" 90 "1~252" 91 "1~252" 92 "1~252" 93 "1~252" 94 "1~252" 95 "1~252" 96 "1~252" 97 "1~252" 98 "1~252" 99 "1~252" 100 "1~252" 101 "1~252" 102 "1~252" 103 "1~252" 104 "1~252" 105 "1~252" 106 "1~252" 107 "1~252" 108 "1~252" 109 "1~252" 110 "1~252" 111 "1~252" 112 "1~252" 113 "1~252" 114 "1~252" 115 "1~252" 116 "1~252" 117 "1~252" 118 "1~252" 119 "1~252" 120 "1~252" 121 "1~252" 122 "1~252" 123 "1~252" 124 "1~252" 125 "1~252" 126 "1~252" 127 "1~252" 128 "1~252" 129 "1~252" 130 "1~252" 131 "1~252" 132 "1~252" 133 "1~252" 134 "1~252" 135 "1~252" 136 "1~252" 137 "1~252" 138 "1~252" 139 "1~252" 140 "1~252" 141 "1~252" 142 "1~252" 143 "1~252" 144 "1~252" 145 "1~252" 146 "1~252" 147 "1~252" 148 "1~252" 149 "1~252" 150 "1~252" 151 "1~252" 152 "1~252" 153 "1~252" 154 "1~252" 155 "1~252" 156 "1~252" 157 "1~252" 158 "1~252" 159 "1~252" 160 "1~252" 161 "1~252" 162 "1~252" 163 "1~252" 164 "1~252" 165 "1~252" 166 "1~252" 167 "1~252" 168 "1~252" 169 "1~252" 170 "1~252" 171 "1~252" 172 "1~252" 173 "1~252" 174 "1~252" 175 "1~252" 176 "1~252" 177 "1~252" 178 "1~252" 179 "1~252" 180 "1~252" 181 "1~252" 182 "1~252" 183 "1~252" 184 "1~252" 185 "1~252" 186 "1~252" 187 "1~252" 188 "1~252" 189 "1~252" 190 "1~252" 191 "1~252" 192 "1~252" 193 "1~252" 194 "1~252" 195 "1~252" 196 "1~252" 197 "1~252" 198 "1~252" 199 "1~252" 200 "1~252" 201 "1~252" 202 "1~252" 203 "1~252" 204 "1~252" 205 "1~252" 206 "1~252" 207 "1~252" 208 "1~252" 209 "1~252" 210 "1~252" 211 "1~252" 212 "1~252" 213 "1~252" 214 "1~252" 215 "1~252" 216 "1~252" 217 "1~252" 218 "1~252" 219 "1~252" 220 "1~252" 221 "1~252" 222 "1~252" 223 "1~252" 224 "1~252" 225 "1~252" 226 "1~252" 227 "1~252" 228 "1~252" 229 "1~252" 230 "1~252" 231 "1~252" 232 "1~252" 233 "1~252" 234 "1~252" 235 "1~252" 236 "1~252" 237 "1~252" 238 "1~252" 239 "1~252" 240 "1~252" 241 "1~252" 242 "1~252" 243 "1~252" 244 "1~252" 245 "1~252" 246 "1~252" 247 "1~252" 248 "1~252" 249 "1~252" 250 "1~252" 251 "1~252" 252 "1~252" 253 "LHD Conditional No Passing ZONE" 254 "RHD Conditional No Passing ZONE" 255 "Invalid";
VAL_ 506 ISLA_SpdwOffst 0 "No Recognition" 1 "1~252 kph or mph" 2 "1~252 kph or mph" 3 "1~252 kph or mph" 4 "1~252 kph or mph" 5 "1~252 kph or mph" 6 "1~252 kph or mph" 7 "1~252 kph or mph" 8 "1~252 kph or mph" 9 "1~252 kph or mph" 10 "1~252 kph or mph" 11 "1~252 kph or mph" 12 "1~252 kph or mph" 13 "1~252 kph or mph" 14 "1~252 kph or mph" 15 "1~252 kph or mph" 16 "1~252 kph or mph" 17 "1~252 kph or mph" 18 "1~252 kph or mph" 19 "1~252 kph or mph" 20 "1~252 kph or mph" 21 "1~252 kph or mph" 22 "1~252 kph or mph" 23 "1~252 kph or mph" 24 "1~252 kph or mph" 25 "1~252 kph or mph" 26 "1~252 kph or mph" 27 "1~252 kph or mph" 28 "1~252 kph or mph" 29 "1~252 kph or mph" 30 "1~252 kph or mph" 31 "1~252 kph or mph" 32 "1~252 kph or mph" 33 "1~252 kph or mph" 34 "1~252 kph or mph" 35 "1~252 kph or mph" 36 "1~252 kph or mph" 37 "1~252 kph or mph" 38 "1~252 kph or mph" 39 "1~252 kph or mph" 40 "1~252 kph or mph" 41 "1~252 kph or mph" 42 "1~252 kph or mph" 43 "1~252 kph or mph" 44 "1~252 kph or mph" 45 "1~252 kph or mph" 46 "1~252 kph or mph" 47 "1~252 kph or mph" 48 "1~252 kph or mph" 49 "1~252 kph or mph" 50 "1~252 kph or mph" 51 "1~252 kph or mph" 52 "1~252 kph or mph" 53 "1~252 kph or mph" 54 "1~252 kph or mph" 55 "1~252 kph or mph" 56 "1~252 kph or mph" 57 "1~252 kph or mph" 58 "1~252 kph or mph" 59 "1~252 kph or mph" 60 "1~252 kph or mph" 61 "1~252 kph or mph" 62 "1~252 kph or mph" 63 "1~252 kph or mph" 64 "1~252 kph or mph" 65 "1~252 kph or mph" 66 "1~252 kph or mph" 67 "1~252 kph or mph" 68 "1~252 kph or mph" 69 "1~252 kph or mph" 70 "1~252 kph or mph" 71 "1~252 kph or mph" 72 "1~252 kph or mph" 73 "1~252 kph or mph" 74 "1~252 kph or mph" 75 "1~252 kph or mph" 76 "1~252 kph or mph" 77 "1~252 kph or mph" 78 "1~252 kph or mph" 79 "1~252 kph or mph" 80 "1~252 kph or mph" 81 "1~252 kph or mph" 82 "1~252 kph or mph" 83 "1~252 kph or mph" 84 "1~252 kph or mph" 85 "1~252 kph or mph" 86 "1~252 kph or mph" 87 "1~252 kph or mph" 88 "1~252 kph or mph" 89 "1~252 kph or mph" 90 "1~252 kph or mph" 91 "1~252 kph or mph" 92 "1~252 kph or mph" 93 "1~252 kph or mph" 94 "1~252 kph or mph" 95 "1~252 kph or mph" 96 "1~252 kph or mph" 97 "1~252 kph or mph" 98 "1~252 kph or mph" 99 "1~252 kph or mph" 100 "1~252 kph or mph" 101 "1~252 kph or mph" 102 "1~252 kph or mph" 103 "1~252 kph or mph" 104 "1~252 kph or mph" 105 "1~252 kph or mph" 106 "1~252 kph or mph" 107 "1~252 kph or mph" 108 "1~252 kph or mph" 109 "1~252 kph or mph" 110 "1~252 kph or mph" 111 "1~252 kph or mph" 112 "1~252 kph or mph" 113 "1~252 kph or mph" 114 "1~252 kph or mph" 115 "1~252 kph or mph" 116 "1~252 kph or mph" 117 "1~252 kph or mph" 118 "1~252 kph or mph" 119 "1~252 kph or mph" 120 "1~252 kph or mph" 121 "1~252 kph or mph" 122 "1~252 kph or mph" 123 "1~252 kph or mph" 124 "1~252 kph or mph" 125 "1~252 kph or mph" 126 "1~252 kph or mph" 127 "1~252 kph or mph" 128 "1~252 kph or mph" 129 "1~252 kph or mph" 130 "1~252 kph or mph" 131 "1~252 kph or mph" 132 "1~252 kph or mph" 133 "1~252 kph or mph" 134 "1~252 kph or mph" 135 "1~252 kph or mph" 136 "1~252 kph or mph" 137 "1~252 kph or mph" 138 "1~252 kph or mph" 139 "1~252 kph or mph" 140 "1~252 kph or mph" 141 "1~252 kph or mph" 142 "1~252 kph or mph" 143 "1~252 kph or mph" 144 "1~252 kph or mph" 145 "1~252 kph or mph" 146 "1~252 kph or mph" 147 "1~252 kph or mph" 148 "1~252 kph or mph" 149 "1~252 kph or mph" 150 "1~252 kph or mph" 151 "1~252 kph or mph" 152 "1~252 kph or mph" 153 "1~252 kph or mph" 154 "1~252 kph or mph" 155 "1~252 kph or mph" 156 "1~252 kph or mph" 157 "1~252 kph or mph" 158 "1~252 kph or mph" 159 "1~252 kph or mph" 160 "1~252 kph or mph" 161 "1~252 kph or mph" 162 "1~252 kph or mph" 163 "1~252 kph or mph" 164 "1~252 kph or mph" 165 "1~252 kph or mph" 166 "1~252 kph or mph" 167 "1~252 kph or mph" 168 "1~252 kph or mph" 169 "1~252 kph or mph" 170 "1~252 kph or mph" 171 "1~252 kph or mph" 172 "1~252 kph or mph" 173 "1~252 kph or mph" 174 "1~252 kph or mph" 175 "1~252 kph or mph" 176 "1~252 kph or mph" 177 "1~252 kph or mph" 178 "1~252 kph or mph" 179 "1~252 kph or mph" 180 "1~252 kph or mph" 181 "1~252 kph or mph" 182 "1~252 kph or mph" 183 "1~252 kph or mph" 184 "1~252 kph or mph" 185 "1~252 kph or mph" 186 "1~252 kph or mph" 187 "1~252 kph or mph" 188 "1~252 kph or mph" 189 "1~252 kph or mph" 190 "1~252 kph or mph" 191 "1~252 kph or mph" 192 "1~252 kph or mph" 193 "1~252 kph or mph" 194 "1~252 kph or mph" 195 "1~252 kph or mph" 196 "1~252 kph or mph" 197 "1~252 kph or mph" 198 "1~252 kph or mph" 199 "1~252 kph or mph" 200 "1~252 kph or mph" 201 "1~252 kph or mph" 202 "1~252 kph or mph" 203 "1~252 kph or mph" 204 "1~252 kph or mph" 205 "1~252 kph or mph" 206 "1~252 kph or mph" 207 "1~252 kph or mph" 208 "1~252 kph or mph" 209 "1~252 kph or mph" 210 "1~252 kph or mph" 211 "1~252 kph or mph" 212 "1~252 kph or mph" 213 "1~252 kph or mph" 214 "1~252 kph or mph" 215 "1~252 kph or mph" 216 "1~252 kph or mph" 217 "1~252 kph or mph" 218 "1~252 kph or mph" 219 "1~252 kph or mph" 220 "1~252 kph or mph" 221 "1~252 kph or mph" 222 "1~252 kph or mph" 223 "1~252 kph or mph" 224 "1~252 kph or mph" 225 "1~252 kph or mph" 226 "1~252 kph or mph" 227 "1~252 kph or mph" 228 "1~252 kph or mph" 229 "1~252 kph or mph" 230 "1~252 kph or mph" 231 "1~252 kph or mph" 232 "1~252 kph or mph" 233 "1~252 kph or mph" 234 "1~252 kph or mph" 235 "1~252 kph or mph" 236 "1~252 kph or mph" 237 "1~252 kph or mph" 238 "1~252 kph or mph" 239 "1~252 kph or mph" 240 "1~252 kph or mph" 241 "1~252 kph or mph" 242 "1~252 kph or mph" 243 "1~252 kph or mph" 244 "1~252 kph or mph" 245 "1~252 kph or mph" 246 "1~252 kph or mph" 247 "1~252 kph or mph" 248 "1~252 kph or mph" 249 "1~252 kph or mph" 250 "1~252 kph or mph" 251 "1~252 kph or mph" 252 "1~252 kph or mph" 253 "Unlimited Speed" 254 "Reserved" 255 "Invalid";
VAL_ 506 ISLA_SwIgnoreReq 0 "Allow All Switch Inputs (default)" 1 "-(SET) Switch Input Ignore" 2 "+(SET) Switch Input Ignore" 3 "-(SET) & +(SET) Switch Inputs Ignore";
VAL_ 506 ISLA_SpdChgReq 0 "Default" 1 "Speed Change Request" 2 "Reserved" 3 "Reserved";
VAL_ 506 ISLA_SpdWrn 0 "No Warning" 1 "Warning" 2 "Reserved" 3 "Reserved";
VAL_ 506 ISLA_IcyWrn 0 "No Warning" 1 "Warning" 2 "Reserved" 3 "Reserved";
VAL_ 506 ISLA_SymFlashMod 0 "No Flasing" 1 "Flashing Sign" 2 "Flashing - Arrow Symbol" 3 "Flashing + Arrow Symbol" 4 "Flashing Auto Symbol" 5 "Reserved" 6 "Reserved" 7 "Reserved";
VAL_ 506 ISLA_Popup 0 "No Popup" 1 "MSLA Speed will Change" 2 "MSLA Speed has Changed" 3 "CC_SCC Speed will Change" 4 "CC_SCC Speed has Changed" 5 "Reserved" 6 "Reserved" 7 "Reserved";
VAL_ 506 ISLA_OptUsmSta 0 "None ISLA Option (속도 제한 메뉴 삭제)" 1 "Off" 2 "Warning" 3 "Assist" 4 "Reserved" 5 "Reserved" 6 "Reserved" 7 "Invalid (GRAY)";
VAL_ 506 ISLA_OffstUsmSta 0 "None Offset Function" 1 "-10kph or -5mph" 2 "-5kph or -3mph" 3 "0kph or 0mph" 4 "+5kph or +3mph" 5 "+10kph or +5mph" 6 "Reserved" 7 "Invalid (GRAY)";
VAL_ 506 ISLA_AutoUsmSta 0 "None Auto Function (Delete Menu)" 1 "Auto Off" 2 "Auto On" 3 "Invalid (GRAY)";
VAL_ 506 ISLA_Cntry 0 "Europe/Russia/Australia" 1 "Domestic" 2 "China" 3 "USA" 4 "Canada" 5 "Australia" 6 "Reserved" 7 "Reserved" 8 "Reserved" 9 "Reserved" 10 "Reserved" 11 "Reserved" 12 "Reserved" 13 "Reserved" 14 "Reserved" 15 "Initial Value (default)";
VAL_ 506 ISLA_AddtnlSign 0 "No Recognition (default)" 1 "School Crossing" 16 "Do Not Pass" 17 "Reserved" 18 "Reserved" 19 "Reserved" 20 "Reserved" 21 "Reserved" 22 "Reserved" 23 "Reserved" 24 "Exit" 25 "Roundabout" 26 "Right Curve" 27 "Left Curve" 28 "Winding Road" 29 "Reserved" 30 "Reserved" 31 "Reserved" 2 "Pedestrian Crossing" 3 "Bicycle Crossing" 4 "Reserved" 5 "Reserved" 6 "Reserved" 7 "Reserved" 8 "Stop" 9 "Yield" 10 "Stop Ahead" 11 "Yield Ahead" 12 "Road Construction Ahead" 13 "Lane Reduction" 14 "Reserved" 15 "Reserved";
VAL_ 506 ISLA_SchoolZone 0 "No School Zone" 1 "School Zone" 2 "Reserved" 3 "Reserved";
